VERSION ""

NS_ :

BS_:

BU_: Node

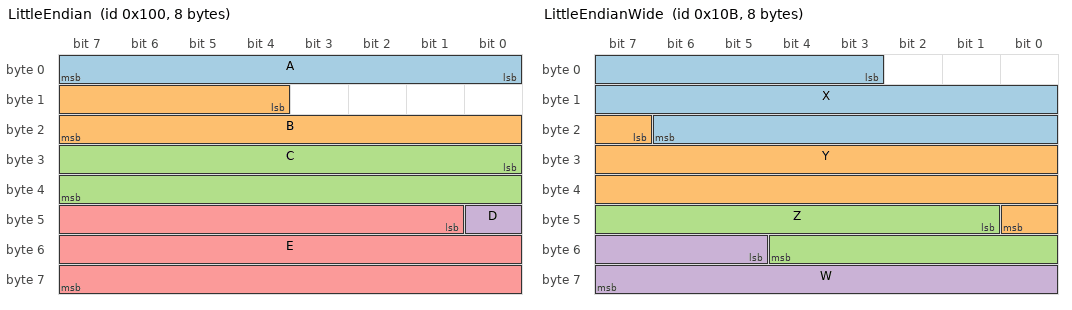
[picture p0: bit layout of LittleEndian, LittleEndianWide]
BO_ 256 LittleEndian: 8 Node
 SG_ A : 0|8@1+ (1,0) [0|0] "" Vector__XXX
 SG_ B : 12|12@1- (0.5,-10) [0|0] "" Vector__XXX
 SG_ C : 24|16@1+ (0.01,0) [0|0] "" Vector__XXX
 SG_ D : 40|1@1+ (1,0) [0|0] "" Vector__XXX
 SG_ E : 41|23@1- (1,0) [0|0] "" Vector__XXX

BO_ 267 LittleEndianWide: 8 Node
 SG_ X : 3|20@1+ (0.001,-3) [0|0] "" Vector__XXX
 SG_ Y : 23|18@1- (1,0) [0|0] "" Vector__XXX
 SG_ Z : 41|12@1+ (2,1) [0|0] "" Vector__XXX
 SG_ W : 53|11@1- (1,0) [0|0] "" Vector__XXX

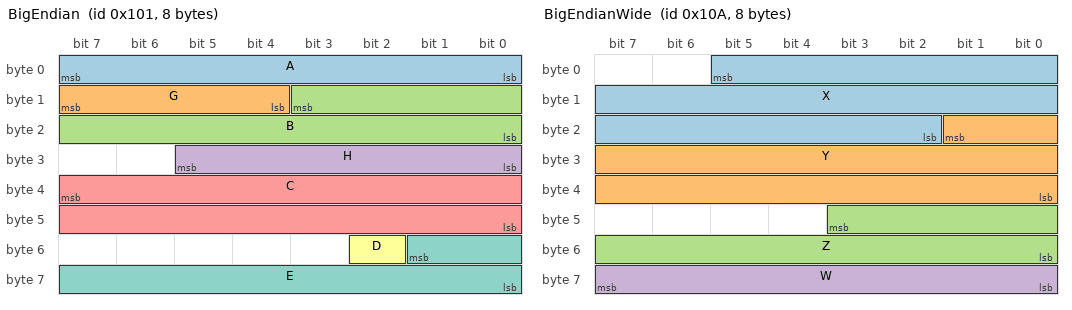
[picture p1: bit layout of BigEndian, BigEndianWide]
BO_ 257 BigEndian: 8 Node
 SG_ A : 7|8@0+ (1,0) [0|0] "" Vector__XXX
 SG_ G : 15|4@0+ (1,0) [0|0] "" Vector__XXX
 SG_ B : 11|12@0- (0.25,5) [0|0] "" Vector__XXX
 SG_ H : 29|6@0+ (1,0) [0|0] "" Vector__XXX
 SG_ C : 39|16@0+ (1,0) [0|0] "" Vector__XXX
 SG_ D : 50|1@0+ (1,0) [0|0] "" Vector__XXX
 SG_ E : 49|10@0- (1,0) [0|0] "" Vector__XXX

BO_ 266 BigEndianWide: 8 Node
 SG_ X : 5|20@0+ (0.001,-3) [0|0] "" Vector__XXX
 SG_ Y : 17|18@0- (1,0) [0|0] "" Vector__XXX
 SG_ Z : 43|12@0+ (2,1) [0|0] "" Vector__XXX
 SG_ W : 63|8@0- (1,0) [0|0] "" Vector__XXX

BO_ 258 Floats: 8 Node
 SG_ F32 : 0|32@1- (1,0) [0|0] "" Vector__XXX
 SG_ F32BE : 39|32@0- (2,1) [0|0] "" Vector__XXX

BO_ 259 Double: 8 Node
 SG_ F64 : 0|64@1- (1,0) [0|0] "" Vector__XXX

BO_ 260 DoubleBigEndian: 8 Node
 SG_ F64BE : 7|64@0- (1,0) [0|0] "" Vector__XXX

BO_ 261 Wide: 8 Node
 SG_ U64 : 0|64@1+ (1,0) [0|0] "" Vector__XXX

BO_ 262 WideBigEndian: 8 Node
 SG_ S64 : 7|64@0- (1,0) [0|0] "" Vector__XXX

BO_ 263 Multiplexed: 8 Node
 SG_ Mux M : 0|8@1+ (1,0) [0|0] "" Vector__XXX
 SG_ S0 m0 : 8|16@1+ (0.1,0) [0|0] "" Vector__XXX
 SG_ S1 m1 : 8|16@1- (1,-100) [0|0] "" Vector__XXX
 SG_ S2 m2 : 8|8@1+ (1,0) [0|0] "" Vector__XXX
 SG_ Common : 56|8@1+ (1,0) [0|0] "" Vector__XXX

BO_ 264 ExtendedMultiplexed: 8 Node
 SG_ Mux1 M : 0|4@1+ (1,0) [0|0] "" Vector__XXX
 SG_ Mux2 m0M : 8|8@1+ (1,0) [0|0] "" Vector__XXX
 SG_ SigA m1 : 16|16@1+ (0.5,0) [0|0] "" Vector__XXX
 SG_ SigB m1 : 32|16@1- (1,0) [0|0] "" Vector__XXX
 SG_ SigC m0 : 48|8@1+ (1,0) [0|0] "" Vector__XXX
 SG_ Always : 56|8@1+ (1,0) [0|0] "" Vector__XXX

BO_ 265 LongFrame: 16 Node
 SG_ L0 : 0|8@1+ (1,0) [0|0] "" Vector__XXX
 SG_ L1 : 87|16@0- (1,0) [0|0] "" Vector__XXX
 SG_ L2 : 100|12@1+ (0.5,0) [0|0] "" Vector__XXX

BO_ 2566844670 EngineController: 8 Node
 SG_ Torque : 16|8@1+ (1,-125) [0|0] "" Vector__XXX
 SG_ Speed : 24|16@1+ (0.125,0) [0|0] "" Vector__XXX

SIG_VALTYPE_ 258 F32 : 1;
SIG_VALTYPE_ 258 F32BE : 1;
SIG_VALTYPE_ 259 F64 : 2;
SIG_VALTYPE_ 260 F64BE : 2;

SG_MUL_VAL_ 264 Mux2 Mux1 0-0;
SG_MUL_VAL_ 264 SigA Mux2 1-1, 3-5;
SG_MUL_VAL_ 264 SigB Mux1 1-2;
SG_MUL_VAL_ 264 SigC Mux2 0-0;
